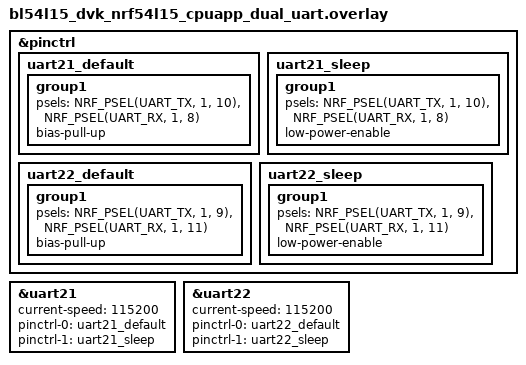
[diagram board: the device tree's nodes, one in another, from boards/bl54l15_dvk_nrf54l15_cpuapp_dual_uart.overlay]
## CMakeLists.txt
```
# SPDX-License-Identifier: Apache-2.0

cmake_minimum_required(VERSION 3.20.0)

find_package(Zephyr REQUIRED HINTS $ENV{ZEPHYR_BASE})
project(uart_high_level_api)

target_sources(app PRIVATE
    src/main.c
    )
```

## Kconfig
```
# UART test configuration options
# Copyright (c) 2024 Nordic Semiconductor ASA
# SPDX-License-Identifier: Apache-2.0

config DUAL_UART_TEST
	bool "Enable dual UART test"

config SETUP_MISMATCH_TEST
	bool "Enable mismatched configuration in dual UART test"

config UART_BAUDRATE_MISMATCH
	int "UART baudrate for DUT_AUX to test mismatch case"
	depends on SETUP_MISMATCH_TEST
	default 9600
	help
	  UART baudrate for DUT_AUX that is intentionally different from DUT
	  to test error detection.

config UART_ELEMENTARY_NO_FLOW_CTRL
	bool "Skip hardware flow control in elementary UART tests"
	help
	  Use UART_CFG_FLOW_CTRL_NONE instead of UART_CFG_FLOW_CTRL_RTS_CTS
	  for boards whose UART driver does not support hardware flow control.

source "Kconfig.zephyr"
```

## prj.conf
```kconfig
CONFIG_SERIAL=y
CONFIG_ZTEST=y
CONFIG_TEST_USERSPACE=y
CONFIG_MAIN_STACK_SIZE=2048
CONFIG_UART_USE_RUNTIME_CONFIGURE=y
CONFIG_UART_INTERRUPT_DRIVEN=y
```

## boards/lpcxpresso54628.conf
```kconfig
CONFIG_UART_ELEMENTARY_NO_FLOW_CTRL=y
```

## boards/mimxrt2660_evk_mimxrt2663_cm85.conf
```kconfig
#
# SPDX-FileCopyrightText: Copyright 2026 NXP
#
# SPDX-License-Identifier: Apache-2.0
#

# The suite's userspace partitions exhaust the M85's 16 MPU regions.
CONFIG_USERSPACE=n
CONFIG_TEST_USERSPACE=n
```

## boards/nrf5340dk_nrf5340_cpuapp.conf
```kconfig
CONFIG_UART_NRFX_UARTE_LEGACY_SHIM=n
```

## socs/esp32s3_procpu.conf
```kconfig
CONFIG_DUAL_UART_TEST=y
```

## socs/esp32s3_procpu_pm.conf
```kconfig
CONFIG_DUAL_UART_TEST=n
```

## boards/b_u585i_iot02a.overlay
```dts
/*
 * Copyright (c) 2025 STMicroelectronics
 *
 * SPDX-License-Identifier: Apache-2.0
 */

dut: &usart3 {
	pinctrl-0 = <&usart3_tx_pd8 &usart3_rx_pd9 &usart3_rts_pd2 &usart3_cts_pb13>;
	dmas = <&gpdma1 29 STM32_DMA_PERIPH_TX>,
	       <&gpdma1 28 STM32_DMA_PERIPH_RX>;
	dma-names = "tx", "rx";
	hw-flow-control;
};
```

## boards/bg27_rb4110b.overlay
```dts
/*
 * Copyright (c) 2025, Silicon Laboratories Inc.
 *
 * SPDX-License-Identifier: Apache-2.0
 */

/*
 * Connect EXP4 (PC3) and EXP6 (PC5) of the Expansion Pin header
 */

dut: &eusart0 {
	compatible = "silabs,eusart-uart";
	pinctrl-0 = <&eusart0_default>;
	pinctrl-names = "default";
	current-speed = <115200>;
	status = "okay";
	/delete-property/ cs-gpios;
};
```

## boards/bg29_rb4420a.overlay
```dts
/*
 * Copyright (c) 2025, Silicon Laboratories Inc.
 *
 * SPDX-License-Identifier: Apache-2.0
 */

/*
 * Connect EXP4 (PC5) and EXP6 (PC3) of the Expansion Pin header
 */

&pinctrl {
	usart0_default: usart0_default {
		group0 {
			pins = <USART0_TX_PC5>; /* WPK EXP4 (PC5) */
			drive-push-pull;
			output-high;
		};

		group1 {
			pins = <USART0_RX_PC3>; /* WPK EXP6 (PC3) */
			input-enable;
			silabs,input-filter;
		};
	};
};

dut: &usart0 {
	current-speed = <115200>;
	pinctrl-0 = <&usart0_default>;
	pinctrl-names = "default";
	status = "okay";
};
```

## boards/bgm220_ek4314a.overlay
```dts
/*
 * Copyright (c) 2025, Silicon Laboratories Inc.
 *
 * SPDX-License-Identifier: Apache-2.0
 */

/*
 * Need to connect PB1 (L7) and PB2(L8) of the MikroE connector
 */

dut: &euart0 {
	compatible = "silabs,eusart-uart";
	pinctrl-0 = <&euart0_default>;
	pinctrl-names = "default";
	current-speed = <115200>;
	status = "okay";
};
```

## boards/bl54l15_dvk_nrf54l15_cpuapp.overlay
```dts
/*
 * Copyright (c) 2024 Nordic Semiconductor ASA
 * Copyright (c) 2025 Ezurio LLC
 *
 * SPDX-License-Identifier: Apache-2.0
 */

&pinctrl {
	uart21_default: uart21_default {
		group1 {
			psels = <NRF_PSEL(UART_TX, 1, 10)>,
				<NRF_PSEL(UART_RX, 1, 11)>,
				<NRF_PSEL(UART_RTS, 1, 8)>,
				<NRF_PSEL(UART_CTS, 1, 9)>;
		};
	};

	uart21_sleep: uart21_sleep {
		group1 {
			psels = <NRF_PSEL(UART_TX, 1, 10)>,
				<NRF_PSEL(UART_RX, 1, 11)>,
				<NRF_PSEL(UART_RTS, 1, 8)>,
				<NRF_PSEL(UART_CTS, 1, 9)>;
			low-power-enable;
		};
	};
};

dut: &uart21 {
	current-speed = <115200>;
	pinctrl-0 = <&uart21_default>;
	pinctrl-1 = <&uart21_sleep>;
	pinctrl-names = "default", "sleep";
	hw-flow-control;
	status = "okay";
};
```

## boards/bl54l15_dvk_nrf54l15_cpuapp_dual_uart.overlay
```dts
/*
 * Copyright (c) 2024 Nordic Semiconductor ASA
 * Copyright (c) 2025 Ezurio LLC
 *
 * SPDX-License-Identifier: Apache-2.0
 */

&pinctrl {
	uart21_default: uart21_default {
		group1 {
			psels = <NRF_PSEL(UART_TX, 1, 10)>,
				<NRF_PSEL(UART_RX, 1, 8)>;
			bias-pull-up;
		};
	};

	uart21_sleep: uart21_sleep {
		group1 {
			psels = <NRF_PSEL(UART_TX, 1, 10)>,
				<NRF_PSEL(UART_RX, 1, 8)>;
			low-power-enable;
		};
	};

	uart22_default: uart22_default {
		group1 {
			psels = <NRF_PSEL(UART_TX, 1, 9)>,
				<NRF_PSEL(UART_RX, 1, 11)>;
			bias-pull-up;
		};
	};

	uart22_sleep: uart22_sleep {
		group1 {
			psels = <NRF_PSEL(UART_TX, 1, 9)>,
				<NRF_PSEL(UART_RX, 1, 11)>;
			low-power-enable;
		};
	};
};

dut: &uart21 {
	current-speed = <115200>;
	pinctrl-0 = <&uart21_default>;
	pinctrl-1 = <&uart21_sleep>;
	pinctrl-names = "default", "sleep";
	status = "okay";
};

dut_aux: &uart22 {
	current-speed = <115200>;
	pinctrl-0 = <&uart22_default>;
	pinctrl-1 = <&uart22_sleep>;
	pinctrl-names = "default", "sleep";
	status = "okay";
};
```

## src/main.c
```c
/*
 * Copyright (c) 2024 Nordic Semiconductor ASA
 *
 * SPDX-License-Identifier: Apache-2.0
 */

/**
 * @addtogroup t_driver_uart
 * @{
 * @defgroup t_uart_elementary test_uart_elementary
 * @}
 */

#include <string.h>

#include <zephyr/drivers/uart.h>
#include <zephyr/pm/device_runtime.h>
#include <zephyr/pm/pm.h>
#include <zephyr/ztest.h>

#if DT_NODE_EXISTS(DT_NODELABEL(dut))
#define UART_NODE DT_NODELABEL(dut)
#else
#define UART_NODE DT_CHOSEN(zephyr_console)
#endif

#if DT_NODE_EXISTS(DT_NODELABEL(dut_aux))
#define UART_NODE_AUX DT_NODELABEL(dut_aux)
#else
#define UART_NODE_AUX DT_CHOSEN(zephyr_console)
#endif

#define SLEEP_TIME_US 1000
#define TEST_BUFFER_LEN 10

#define UART_BAUDRATE DT_PROP_OR(UART_NODE, current_speed, 115200)

static const struct device *const uart_dev = DEVICE_DT_GET(UART_NODE);

const uint8_t test_pattern[TEST_BUFFER_LEN] = { 0x11, 0x12, 0x13, 0x14, 0x15,
						0x16, 0x17, 0x18, 0x19, 0x20 };
static uint8_t test_buffer[TEST_BUFFER_LEN];
static volatile uint8_t uart_error_counter;

#if defined(CONFIG_DUAL_UART_TEST)
static const struct device *const uart_dev_aux = DEVICE_DT_GET(UART_NODE_AUX);
static uint8_t test_buffer_aux[TEST_BUFFER_LEN];
static volatile uint8_t aux_uart_error;
static volatile uint8_t aux_uart_error_counter;
#endif

/*
 * ISR for UART TX action
 */
static void uart_tx_interrupt_service(const struct device *dev, int *tx_byte_offset)
{
	uint8_t bytes_sent = 0;
	uint8_t *tx_data_pointer = (uint8_t *)(test_pattern + *tx_byte_offset);

	if (*tx_byte_offset < TEST_BUFFER_LEN) {
		bytes_sent = uart_fifo_fill(dev, tx_data_pointer, 1);
		*tx_byte_offset += bytes_sent;
	} else {
		*tx_byte_offset = 0;
		uart_irq_tx_disable(dev);
	}
}

/*
 * ISR for UART RX action
 */
static void uart_rx_interrupt_service(const struct device *dev, uint8_t *receive_buffer_pointer,
				      int *rx_byte_offset)
{
	int rx_data_length = 0;

	do {
		rx_data_length = uart_fifo_read(dev, receive_buffer_pointer + *rx_byte_offset,
						TEST_BUFFER_LEN);
		*rx_byte_offset += rx_data_length;
	} while (rx_data_length);
}

/*
 * Callback function for MAIN UART interrupt based transmission test
 */
static void interrupt_driven_uart_callback_main_uart(const struct device *dev, void *user_data)
{
	int err;
	static int tx_byte_offset;
	static int rx_byte_offset;

	uart_irq_update(dev);
	err = uart_err_check(dev);
	if (err != 0) {
		uart_error_counter++;
	}
	while (uart_irq_is_pending(dev)) {
		if (uart_irq_rx_ready(dev)) {
			uart_rx_interrupt_service(dev, (uint8_t *)user_data, &rx_byte_offset);
		}
		if (uart_irq_tx_ready(dev)) {
			uart_tx_interrupt_service(dev, &tx_byte_offset);
		}
		uart_irq_update(dev);
	}
}

#if defined(CONFIG_DUAL_UART_TEST)
/*
 * Callback function for AUX UART interrupt based transmission test
 */
static void interrupt_driven_uart_callback_aux_uart(const struct device *dev, void *user_data)
{
	int err;
	static int tx_byte_offset_aux;
	static int rx_byte_offset_aux;

	uart_irq_update(dev);
	err = uart_err_check(dev);
	if (err != 0) {
		aux_uart_error_counter++;
	}
	while (uart_irq_is_pending(dev)) {
		if (uart_irq_rx_ready(dev)) {
			uart_rx_interrupt_service(dev, (uint8_t *)user_data, &rx_byte_offset_aux);
		}
		if (uart_irq_tx_ready(dev)) {
			uart_tx_interrupt_service(dev, &tx_byte_offset_aux);
		}
		uart_irq_update(dev);
	}
}
#endif /* CONFIG_DUAL_UART_TEST */

/*
 * Test UART proper configuration call
 */
ZTEST(uart_elementary, test_uart_proper_configuration)
{
	Z_TEST_SKIP_IFDEF(CONFIG_DUAL_UART_TEST);

	int err;
	struct uart_config test_expected_uart_config;
	struct uart_config test_uart_config = {
		.baudrate = UART_BAUDRATE,
		.parity = UART_CFG_PARITY_NONE,
		.stop_bits = UART_CFG_STOP_BITS_1,
		.data_bits = UART_CFG_DATA_BITS_8,
		.flow_ctrl = IS_ENABLED(CONFIG_UART_ELEMENTARY_NO_FLOW_CTRL)
				? UART_CFG_FLOW_CTRL_NONE
				: UART_CFG_FLOW_CTRL_RTS_CTS,
	};

	err = uart_configure(uart_dev, &test_uart_config);
	zassert_equal(err, 0, "'uart_configure' api call - unexpected error: %d", err);

	err = uart_config_get(uart_dev, &test_expected_uart_config);
	zassert_equal(err, 0, "'uart_config_get' api call - unexpected error raised : %d", err);

	zassert_equal(test_uart_config.baudrate, test_expected_uart_config.baudrate,
		      "Set and actual UART config baudrate mismatch: %d != %d",
		      test_uart_config.baudrate, test_expected_uart_config.baudrate);

	zassert_equal(test_uart_config.parity, test_expected_uart_config.parity,
		      "Set and actual UART config parity mismatch: %d != %d",
		      test_uart_config.parity, test_expected_uart_config.parity);

	zassert_equal(test_uart_config.stop_bits, test_expected_uart_config.stop_bits,
		      "Set and actual UART config stop_bits mismatch: %d != %d",
		      test_uart_config.stop_bits, test_expected_uart_config.stop_bits);

	zassert_equal(test_uart_config.data_bits, test_expected_uart_config.data_bits,
		      "Set and actual UART config data_bits mismatch: %d != %d",
		      test_uart_config.data_bits, test_expected_uart_config.data_bits);

	zassert_equal(test_uart_config.flow_ctrl, test_expected_uart_config.flow_ctrl,
		      "Set and actual UART config flow_ctrl mismatch: %d != %d",
		      test_uart_config.flow_ctrl, test_expected_uart_config.flow_ctrl);
}

/*
 * Test UART improper configuration call
 */
ZTEST(uart_elementary, test_uart_improper_configuration)
{
	Z_TEST_SKIP_IFDEF(CONFIG_DUAL_UART_TEST);

	int err;
	struct uart_config test_uart_config = {
		.baudrate = UART_BAUDRATE,
		.parity = 7,
		.stop_bits = UART_CFG_STOP_BITS_1,
		.data_bits = UART_CFG_DATA_BITS_8,
		.flow_ctrl = IS_ENABLED(CONFIG_UART_ELEMENTARY_NO_FLOW_CTRL)
				? UART_CFG_FLOW_CTRL_NONE
				: UART_CFG_FLOW_CTRL_RTS_CTS,
	};

	err = uart_configure(uart_dev, &test_uart_config);
	zassert_not_equal(
		err, 0,
		"'uart_configure' with incorrect configuration has not raised an error, err=%d",
		err);
}

#if !defined(CONFIG_DUAL_UART_TEST)
/*
 * Test UART basic interrupt based transmission (with loopback)
 */
ZTEST(uart_elementary, test_uart_basic_transmission)
{
	int err;
	struct uart_config test_uart_config = {
		.baudrate = UART_BAUDRATE,
		.parity = UART_CFG_PARITY_ODD,
		.stop_bits = UART_CFG_STOP_BITS_1,
		.data_bits = UART_CFG_DATA_BITS_8,
		.flow_ctrl = IS_ENABLED(CONFIG_UART_ELEMENTARY_NO_FLOW_CTRL)
				? UART_CFG_FLOW_CTRL_NONE
				: UART_CFG_FLOW_CTRL_RTS_CTS,
	};

	err = uart_configure(uart_dev, &test_uart_config);
	zassert_equal(err, 0, "Unexpected error when configuring UART0: %d", err);

	err = uart_irq_callback_set(uart_dev, interrupt_driven_uart_callback_main_uart);
	zassert_equal(err, 0, "Unexpected error when setting callback %d", err);
	err = uart_irq_callback_user_data_set(uart_dev, interrupt_driven_uart_callback_main_uart,
					      (void *)test_buffer);
	zassert_equal(err, 0, "Unexpected error when setting user data for callback %d", err);
	uart_irq_err_enable(uart_dev);
	uart_irq_rx_enable(uart_dev);
	uart_irq_tx_enable(uart_dev);

	/* wait for the tramission to finish (no polling is intentional) */
	k_sleep(K_USEC(100 * SLEEP_TIME_US));

	uart_irq_tx_disable(uart_dev);
	uart_irq_rx_disable(uart_dev);
	uart_irq_err_disable(uart_dev);
	for (int index = 0; index < TEST_BUFFER_LEN; index++) {
		zassert_equal(test_buffer[index], test_pattern[index],
			      "Received data byte %d does not match pattern 0x%x != 0x%x", index,
			      test_buffer[index], test_pattern[index]);
	}
}

static int reconfigure_tx_offset;
static int reconfigure_rx_offset;

/*
 * Callback function for the UART reconfiguration test
 */
static void uart_reconfigure_callback(const struct device *dev, void *user_data)
{
	int err;

	uart_irq_update(dev);
	err = uart_err_check(dev);
	if (err != 0) {
		uart_error_counter++;
	}
	while (uart_irq_is_pending(dev)) {
		if (uart_irq_rx_ready(dev)) {
			uart_rx_interrupt_service(dev, (uint8_t *)user_data,
						  &reconfigure_rx_offset);
		}
		if (uart_irq_tx_ready(dev)) {
			uart_tx_interrupt_service(dev, &reconfigure_tx_offset);
		}
		uart_irq_update(dev);
	}
}

/*
 * Test UART interrupt based transmission after configuring the UART with its interrupts enabled
 */
ZTEST(uart_elementary, test_uart_configure_with_irq_enabled)
{
	int err;
	struct uart_config test_uart_config = { .baudrate = UART_BAUDRATE,
						.parity = UART_CFG_PARITY_ODD,
						.stop_bits = UART_CFG_STOP_BITS_1,
						.data_bits = UART_CFG_DATA_BITS_8,
						.flow_ctrl = UART_CFG_FLOW_CTRL_NONE };

	reconfigure_tx_offset = 0;
	reconfigure_rx_offset = 0;
	uart_error_counter = 0;
	memset(test_buffer, 0, sizeof(test_buffer));

	err = uart_irq_callback_user_data_set(uart_dev, uart_reconfigure_callback,
					      (void *)test_buffer);
	zassert_equal(err, 0, "Unexpected error when setting callback %d", err);
	uart_irq_err_enable(uart_dev);
	uart_irq_rx_enable(uart_dev);

	/* the interrupts enabled before the configuration stay enabled */
	err = uart_configure(uart_dev, &test_uart_config);
	zassert_equal(err, 0, "Unexpected error when configuring UART0: %d", err);

	uart_irq_tx_enable(uart_dev);

	/* wait for the transmission to finish (no polling is intentional) */
	k_sleep(K_USEC(100 * SLEEP_TIME_US));

	uart_irq_tx_disable(uart_dev);
	uart_irq_rx_disable(uart_dev);
	uart_irq_err_disable(uart_dev);

	zassert_equal(uart_error_counter, 0, "UART errors reported: %d", uart_error_counter);
	for (int index = 0; index < TEST_BUFFER_LEN; index++) {
		zassert_equal(test_buffer[index], test_pattern[index],
			      "Received data byte %d does not match pattern 0x%x != 0x%x", index,
			      test_buffer[index], test_pattern[index]);
	}
}

#if defined(CONFIG_PM)
static int pm_tx_offset;
static int pm_rx_offset;
static atomic_t pm_state_entered;

static void pm_state_entry(enum pm_state state)
{
	ARG_UNUSED(state);

	atomic_inc(&pm_state_entered);
}

static struct pm_notifier pm_light_sleep_notifier = {
	.state_entry = pm_state_entry,
};

static void uart_pm_callback(const struct device *dev, void *user_data)
{
	int err;

	uart_irq_update(dev);

	err = uart_err_check(dev);
	if (err != 0) {
		uart_error_counter++;
	}

	while (uart_irq_is_pending(dev)) {
		if (uart_irq_rx_ready(dev)) {
			uart_rx_interrupt_service(dev, (uint8_t *)user_data, &pm_rx_offset);
		}

		if (uart_irq_tx_ready(dev)) {
			uart_tx_interrupt_service(dev, &pm_tx_offset);
		}

		uart_irq_update(dev);
	}
}

/*
 * Test UART interrupt transmission across light sleep.
 *
 * First idle is after configure (fresh peripheral state). Second idle is after a
 * completed IRQ TX/RX burst, when PM locks have been taken and released — a
 * different driver state than post-configure alone.
 */
ZTEST(uart_elementary, test_uart_pm_light_sleep)
{
	int err;
	struct uart_config test_uart_config = {.baudrate = UART_BAUDRATE,
					       .parity = UART_CFG_PARITY_ODD,
					       .stop_bits = UART_CFG_STOP_BITS_1,
					       .data_bits = UART_CFG_DATA_BITS_8,
					       .flow_ctrl = UART_CFG_FLOW_CTRL_RTS_CTS};

	err = uart_configure(uart_dev, &test_uart_config);
	zassert_equal(err, 0, "Unexpected error when configuring UART0: %d", err);

	err = uart_irq_callback_user_data_set(uart_dev, uart_pm_callback, (void *)test_buffer);
	zassert_equal(err, 0, "Unexpected error when setting callback %d", err);

	pm_notifier_register(&pm_light_sleep_notifier);

	for (int tx_cycle = 0; tx_cycle < 2; tx_cycle++) {
		atomic_clear(&pm_state_entered);
		k_sleep(K_MSEC(100));
		zassert_true(atomic_get(&pm_state_entered) > 0,
			     "System stayed active during the idle window");

		pm_tx_offset = 0;
		pm_rx_offset = 0;
		uart_error_counter = 0;
		memset(test_buffer, 0, sizeof(test_buffer));
		uart_irq_err_enable(uart_dev);
		uart_irq_rx_enable(uart_dev);
		uart_irq_tx_enable(uart_dev);

		/* wait for the tramission to finish (no polling is intentional) */
		k_sleep(K_USEC(100 * SLEEP_TIME_US));

		uart_irq_tx_disable(uart_dev);
		uart_irq_rx_disable(uart_dev);
		uart_irq_err_disable(uart_dev);

		zassert_equal(uart_error_counter, 0, "UART errors reported after light sleep: %d",
			      uart_error_counter);

		for (int index = 0; index < TEST_BUFFER_LEN; index++) {
			zassert_equal(test_buffer[index], test_pattern[index],
				      "Received data byte %d does not match pattern 0x%x != 0x%x",
				      index, test_buffer[index], test_pattern[index]);
		}
	}

	pm_notifier_unregister(&pm_light_sleep_notifier);
}
#endif /* CONFIG_PM */
#else
/*
 * Test UART interrupt based transmission between two ports
 */
ZTEST(uart_elementary, test_uart_dual_port_transmission)
{
	int err;
	struct uart_config test_uart_config = { .baudrate = UART_BAUDRATE,
						.parity = UART_CFG_PARITY_EVEN,
						.stop_bits = UART_CFG_STOP_BITS_2,
						.data_bits = UART_CFG_DATA_BITS_8,
						.flow_ctrl = UART_CFG_FLOW_CTRL_NONE };

#if defined(CONFIG_SETUP_MISMATCH_TEST)
	struct uart_config test_uart_config_aux = { .baudrate = CONFIG_UART_BAUDRATE_MISMATCH,
						    .parity = UART_CFG_PARITY_EVEN,
						    .stop_bits = UART_CFG_STOP_BITS_2,
						    .data_bits = UART_CFG_DATA_BITS_8,
						    .flow_ctrl = UART_CFG_FLOW_CTRL_NONE };
#endif
	err = uart_configure(uart_dev, &test_uart_config);
	zassert_equal(err, 0, "Unexpected error when configuring UART0: %d", err);

#if defined(CONFIG_SETUP_MISMATCH_TEST)
	err = uart_configure(uart_dev_aux, &test_uart_config_aux);
#else
	err = uart_configure(uart_dev_aux, &test_uart_config);
#endif

	zassert_equal(err, 0, "Unexpected error when configuring UART1: %d", err);

	err = uart_irq_callback_set(uart_dev, interrupt_driven_uart_callback_main_uart);
	zassert_equal(err, 0, "Unexpected error when setting callback for UART0 %d", err);
	err = uart_irq_callback_user_data_set(uart_dev, interrupt_driven_uart_callback_main_uart,
					      (void *)test_buffer);
	zassert_equal(err, 0, "Unexpected error when setting user data for UART0 callback %d", err);

	err = uart_irq_callback_set(uart_dev_aux, interrupt_driven_uart_callback_aux_uart);
	zassert_equal(err, 0, "Unexpected error when setting callback for UART1 %d", err);
	err = uart_irq_callback_user_data_set(uart_dev_aux, interrupt_driven_uart_callback_aux_uart,
					      (void *)test_buffer_aux);
	zassert_equal(err, 0, "Unexpected error when setting user data for UART1 callback %d", err);

	if (IS_ENABLED(CONFIG_PM_DEVICE_RUNTIME)) {
		int usage = pm_device_runtime_usage(uart_dev);
		int usage_aux = pm_device_runtime_usage(uart_dev_aux);

		zassert_equal(usage, 0);
		zassert_equal(usage_aux, 0);
		pm_device_runtime_get(uart_dev);
		pm_device_runtime_get(uart_dev_aux);
	}

	uart_irq_err_enable(uart_dev);
	uart_irq_err_enable(uart_dev_aux);

	uart_irq_rx_enable(uart_dev);
	uart_irq_rx_enable(uart_dev_aux);

	uart_irq_tx_enable(uart_dev);
	uart_irq_tx_enable(uart_dev_aux);

	/* wait for the tramission to finish (no polling is intentional) */
	k_sleep(K_USEC(100 * SLEEP_TIME_US));

	uart_irq_tx_disable(uart_dev);
	uart_irq_tx_disable(uart_dev_aux);
	uart_irq_rx_disable(uart_dev);
	uart_irq_rx_disable(uart_dev_aux);
	uart_irq_err_disable(uart_dev);
	uart_irq_err_disable(uart_dev_aux);

	if (IS_ENABLED(CONFIG_PM_DEVICE_RUNTIME)) {
		pm_device_runtime_put(uart_dev);
		pm_device_runtime_put(uart_dev_aux);

		int usage = pm_device_runtime_usage(uart_dev);
		int usage_aux = pm_device_runtime_usage(uart_dev_aux);

		zassert_equal(usage, 0);
		zassert_equal(usage_aux, 0);
	}

#if defined(CONFIG_SETUP_MISMATCH_TEST)
	TC_PRINT("Mismatched configuration test\n");
	zassert_not_equal(uart_error_counter + aux_uart_error_counter, 0,
			  "UART configuration mismatch error not detected");

#else
	for (int index = 0; index < TEST_BUFFER_LEN; index++) {
		zassert_equal(test_buffer[index], test_pattern[index],
			      "UART0 received data byte %d does not match pattern 0x%x != 0x%x",
			      index, test_buffer[index], test_pattern[index]);
		zassert_equal(test_buffer_aux[index], test_pattern[index],
			      "UART1 received data byte %d does not match pattern 0x%x != 0x%x",
			      index, test_buffer_aux[index], test_pattern[index]);
	}
#endif /* CONFIG_SETUP_MISMATCH_TEST */
}
#endif /* CONFIG_DUAL_UART_TEST */

/*
 * Test setup
 */
void *test_setup(void)
{
	zassert_true(device_is_ready(uart_dev), "UART0 device is not ready");
#if defined(CONFIG_DUAL_UART_TEST)
	zassert_true(device_is_ready(uart_dev_aux), "UART1 device is not ready");
#endif

	return NULL;
}

ZTEST_SUITE(uart_elementary, NULL, test_setup, NULL, NULL, NULL);
```
